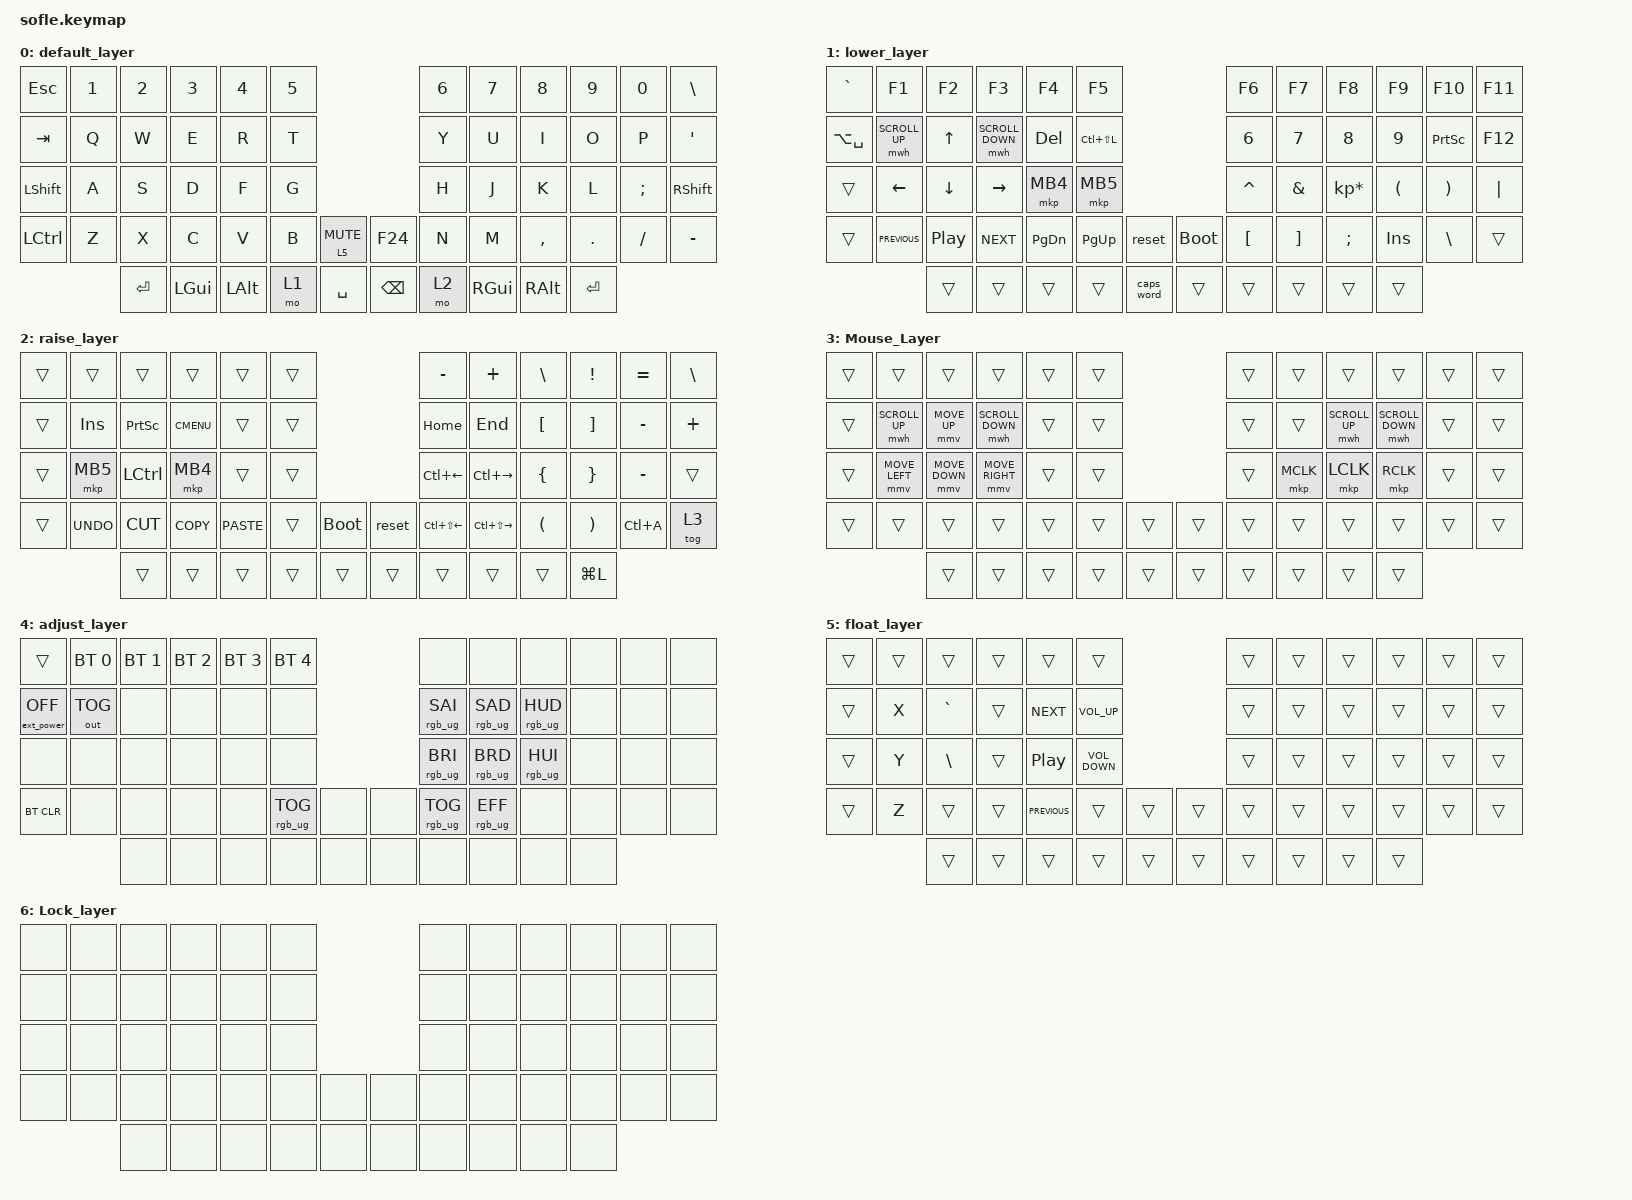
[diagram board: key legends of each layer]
/*
 * Copyright (c) 2020 The ZMK Contributors
 *
 * SPDX-License-Identifier: MIT
 */

#include <dt-bindings/led/led.h>
#include <behaviors.dtsi>
#include <dt-bindings/zmk/bt.h>
#include <dt-bindings/zmk/ext_power.h>
#include <dt-bindings/zmk/keys.h>
#include <dt-bindings/zmk/mouse.h>
#include <dt-bindings/zmk/outputs.h>
#include <dt-bindings/zmk/rgb.h>

#define BASE 0
#define LOWER 1
#define RAISE 2
#define MOUSE 3
#define ADJUST 4
#define U_MOUSE_MOVE_MAX 1800   				 /* <--- New max speed setting (default: 600) */

#undef MOVE_UP
#undef MOVE_DOWN
#undef MOVE_LEFT
#undef MOVE_RIGHT

#define MOVE_UP MOVE_VERT(-U_MOUSE_MOVE_MAX)
#define MOVE_DOWN MOVE_VERT(U_MOUSE_MOVE_MAX)
#define MOVE_LEFT MOVE_HOR(-U_MOUSE_MOVE_MAX)
#define MOVE_RIGHT MOVE_HOR(U_MOUSE_MOVE_MAX)
#define U_MOUSE_SCROLL_MAX 150                    /* <--- New max speed setting (default: 10) */

#undef SCROLL_UP
#undef SCROLL_DOWN
#undef SCROLL_LEFT
#undef SCROLL_RIGHT

#define SCROLL_UP SCROLL_VERT(U_MOUSE_SCROLL_MAX)
#define SCROLL_DOWN SCROLL_VERT(-U_MOUSE_SCROLL_MAX)
#define SCROLL_LEFT SCROLL_HOR(-U_MOUSE_SCROLL_MAX)
#define SCROLL_RIGHT SCROLL_HOR(U_MOUSE_SCROLL_MAX)

&mmv { time-to-max-speed-ms = <2000>; };

&spi1 {
    compatible = "nordic,nrf-spim";
    status = "okay";
    mosi-pin = <8>;

    // Unused pins, needed for SPI definition, but not used by the ws2812 driver itself.

    sck-pin = <5>;
    miso-pin = <7>;

    led_strip: ws2812@0 {
        compatible = "worldsemi,ws2812-spi";
        label = "WS2812";

        /* SPI */

        reg = <0>; /* ignored, but necessary for SPI bindings */
        spi-max-frequency = <4000000>;

        /* WS2812 */

        chain-length = <30>;
        spi-one-frame = <0x70>;
        spi-zero-frame = <0x40>;
        color-mapping = <LED_COLOR_ID_GREEN LED_COLOR_ID_RED LED_COLOR_ID_BLUE>;
    };
};

/ {
    chosen { zmk,underglow = &led_strip; };
};

&mwh {
    acceleration-exponent = <1>;
    time-to-max-speed-ms = <2000>;
};

&mwh {
};

&sk {
    release-after-ms = <250>;
    quick-release;
    ignore-modifiers;
};

/ {
    // Activate ADJUST layer by pressing raise and lower

    conditional_layers {
        compatible = "zmk,conditional-layers";

        adjust_layer {
            if-layers = <1 2>;
            then-layer = <4>;
        };
    };

    behaviors {
        mo_tog: behavior_mo_tog {
            compatible = "zmk,behavior-hold-tap";
            label = "mo_tog";
            #binding-cells = <2>;
            flavor = "hold-preferred";
            tapping-term-ms = <125>;
            bindings = <&mo>, <&tog>;
        };

        mouse_tap_layer: mouse_tap_layer {
            compatible = "zmk,behavior-tap-dance";
            label = "MOUSE_TAP_LAYER";
            #binding-cells = <0>;
            bindings = <&mo 2>, <&mo 3>;
        };

        super_backspace: super_backspace {
            compatible = "zmk,behavior-tap-dance";
            label = "SUPER_BACKSPACE";
            #binding-cells = <0>;
            bindings = <&kp BACKSPACE>, <&kp LS(LG(BACKSPACE))>;

            tapping-term-ms = <150>;
        };
    };

    combos {
        compatible = "zmk,combos";

        combo_lock {
            bindings = <&tog 6>;
            key-positions = <53 56 33 26>;
            layers = <0 3 4 1 2 6>;
            timeout-ms = <50>;
        };
    };

    keymap {
        compatible = "zmk,keymap";

        default_layer {
            bindings = <
&kp ESC     &kp N1  &kp N2     &kp N3    &kp N4    &kp N5                                 &kp N6  &kp N7         &kp N8     &kp N9     &kp N0    &kp BACKSLASH
&kp TAB     &kp Q   &kp W      &kp E     &kp R     &kp T                                  &kp Y   &kp U          &kp I      &kp O      &kp P     &kp SQT
&kp LSHIFT  &kp A   &kp S      &kp D     &kp F     &kp G                                  &kp H   &kp J          &kp K      &kp L      &kp SEMI  &kp RIGHT_SHIFT
&kp LCTRL   &kp Z   &kp X      &kp C     &kp V     &kp B   &lt 5 C_MUTE    &kp F24        &kp N   &kp M          &kp COMMA  &kp DOT    &kp FSLH  &kp MINUS
                    &kp ENTER  &kp LGUI  &kp LALT  &mo 1   &kp SPACE       &kp BACKSPACE  &mo 2   &kp RIGHT_GUI  &kp RALT   &kp ENTER
            >;
        };

        lower_layer {
            bindings = <
&kp GRAVE      &kp F1          &kp F2            &kp F3            &kp F4         &kp F5                                    &kp F6     &kp F7    &kp F8           &kp F9      &kp F10          &kp F11
&kp LA(SPACE)  &mwh SCROLL_UP  &kp UP            &mwh SCROLL_DOWN  &kp DELETE     &kp LC(LS(L))                             &kp N6     &kp N7    &kp N8           &kp N9      &kp PRINTSCREEN  &kp F12
&trans         &kp LEFT        &kp DOWN          &kp RIGHT         &mkp MB4       &mkp MB5                                  &kp CARET  &kp AMPS  &kp KP_MULTIPLY  &kp LPAR    &kp RPAR         &kp PIPE
&trans         &kp C_PREVIOUS  &kp C_PLAY_PAUSE  &kp C_NEXT        &kp PAGE_DOWN  &kp PAGE_UP    &reset        &bootloader  &kp LBKT   &kp RBKT  &kp SEMI         &kp INSERT  &kp BSLH         &trans
                               &trans            &trans            &trans         &trans         &caps_word    &trans       &trans     &trans    &trans           &trans
            >;
        };

        raise_layer {
            bindings = <
&trans  &trans      &trans     &trans       &trans       &trans                         &kp MINUS         &kp PLUS           &kp BACKSLASH         &kp EXCL               &kp EQUAL  &kp BACKSLASH
&trans  &kp INS     &kp PSCRN  &kp K_CMENU  &trans       &trans                         &kp HOME          &kp END            &kp LEFT_BRACKET      &kp RIGHT_BRACKET      &kp MINUS  &kp PLUS
&trans  &mkp MB5    &kp LCTRL  &mkp MB4     &trans       &trans                         &kp LC(LEFT)      &kp LC(RIGHT)      &kp LEFT_BRACE        &kp RIGHT_BRACE        &kp MINUS  &trans
&trans  &kp K_UNDO  &kp K_CUT  &kp K_COPY   &kp K_PASTE  &trans  &bootloader    &reset  &kp LC(LS(LEFT))  &kp LC(LS(RIGHT))  &kp LEFT_PARENTHESIS  &kp RIGHT_PARENTHESIS  &kp LC(A)  &tog 3
                    &trans     &trans       &trans       &trans  &trans         &trans  &trans            &trans             &trans                &kp LG(L)
            >;
        };

        Mouse_Layer {
            bindings = <
&trans  &trans          &trans          &trans            &trans  &trans                    &trans  &trans     &trans          &trans            &trans  &trans
&trans  &mwh SCROLL_UP  &mmv MOVE_UP    &mwh SCROLL_DOWN  &trans  &trans                    &trans  &trans     &mwh SCROLL_UP  &mwh SCROLL_DOWN  &trans  &trans
&trans  &mmv MOVE_LEFT  &mmv MOVE_DOWN  &mmv MOVE_RIGHT   &trans  &trans                    &trans  &mkp MCLK  &mkp LCLK       &mkp RCLK         &trans  &trans
&trans  &trans          &trans          &trans            &trans  &trans  &trans    &trans  &trans  &trans     &trans          &trans            &trans  &trans
                        &trans          &trans            &trans  &trans  &trans    &trans  &trans  &trans     &trans          &trans
            >;
        };

        adjust_layer {
            bindings = <
&trans             &bt BT_SEL 0  &bt BT_SEL 1  &bt BT_SEL 2  &bt BT_SEL 3  &bt BT_SEL 4                     &none            &none            &none            &none  &none  &none
&ext_power EP_OFF  &out OUT_TOG  &none         &none         &none         &none                            &rgb_ug RGB_SAI  &rgb_ug RGB_SAD  &rgb_ug RGB_HUD  &none  &none  &none
&none              &none         &none         &none         &none         &none                            &rgb_ug RGB_BRI  &rgb_ug RGB_BRD  &rgb_ug RGB_HUI  &none  &none  &none
&bt BT_CLR         &none         &none         &none         &none         &rgb_ug RGB_TOG  &none    &none  &rgb_ug RGB_TOG  &rgb_ug RGB_EFF  &none            &none  &none  &none
                                 &none         &none         &none         &none            &none    &none  &none            &none            &none            &none
            >;
        };

        float_layer {
            bindings = <
&trans  &trans  &trans     &trans  &trans            &trans                               &trans  &trans  &trans  &trans  &trans  &trans
&trans  &kp X   &kp GRAVE  &trans  &kp C_NEXT        &kp C_VOL_UP                         &trans  &trans  &trans  &trans  &trans  &trans
&trans  &kp Y   &kp BSLH   &trans  &kp C_PLAY_PAUSE  &kp C_VOLUME_DOWN                    &trans  &trans  &trans  &trans  &trans  &trans
&trans  &kp Z   &trans     &trans  &kp C_PREVIOUS    &trans             &trans    &trans  &trans  &trans  &trans  &trans  &trans  &trans
                &trans     &trans  &trans            &trans             &trans    &trans  &trans  &trans  &trans  &trans
            >;
        };

        Lock_layer {
            bindings = <
&none  &none  &none  &none  &none  &none                  &none  &none  &none  &none  &none  &none
&none  &none  &none  &none  &none  &none                  &none  &none  &none  &none  &none  &none
&none  &none  &none  &none  &none  &none                  &none  &none  &none  &none  &none  &none
&none  &none  &none  &none  &none  &none  &none    &none  &none  &none  &none  &none  &none  &none
              &none  &none  &none  &none  &none    &none  &none  &none  &none  &none
            >;
        };
    };
};
